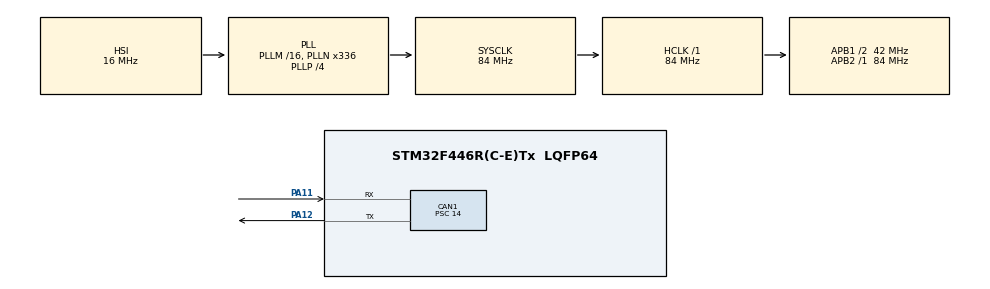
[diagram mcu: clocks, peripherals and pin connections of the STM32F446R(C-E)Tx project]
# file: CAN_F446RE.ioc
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CAN1.BS1=CAN_BS1_2TQ
CAN1.BS2=CAN_BS2_3TQ
CAN1.CalculateBaudRate=499999
CAN1.CalculateTimeBit=2000
CAN1.CalculateTimeQuantum=333.33333333333337
CAN1.Prescaler=14
CAN1.SJW=CAN_SJW_2TQ
Mcu.Family=STM32F4
Mcu.Name=STM32F446R(C-E)Tx
Mcu.Package=LQFP64
NVIC.PriorityGroup=NVIC_PRIORITYGROUP_0
PA11.GPIO_PuPd=GPIO_PULLUP
PA11.Mode=CAN_Activate
PA11.Signal=CAN1_RX
PA12.Mode=CAN_Activate
PA12.Signal=CAN1_TX
ProjectManager.HeapSize=0x200
ProjectManager.StackSize=0x400
ProjectManager.TargetToolchain=STM32CubeIDE
RCC.48MHZClocksFreq_Value=84000000
RCC.AHBFreq_Value=84000000
RCC.APB1CLKDivider=RCC_HCLK_DIV2
RCC.APB1Freq_Value=42000000
RCC.APB1TimFreq_Value=84000000
RCC.APB2Freq_Value=84000000
RCC.APB2TimFreq_Value=84000000
RCC.CortexFreq_Value=84000000
RCC.FLatency-AdvancedSettings=FLASH_LATENCY_2
RCC.HCLKFreq_Value=84000000
RCC.HSE_VALUE=8000000
RCC.HSI_VALUE=16000000
RCC.PLLN=336
RCC.PLLP=RCC_PLLP_DIV4
RCC.SYSCLKFreq_VALUE=84000000
RCC.SYSCLKSource=RCC_SYSCLKSOURCE_PLLCLK
RCC.USBFreq_Value=168000000
RCC.VCOOutputFreq_Value=336000000
board=NUCLEO-F446RE

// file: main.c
/* USER CODE BEGIN Header */
/**
  ******************************************************************************
  * @file           : main.c
  * @brief          : Main program body
  * Author	    : Le Viet Duc
  ******************************************************************************
  * @attention
  *
  * Copyright (c) 2024 STMicroelectronics.
  * All rights reserved.
  *
  * This software is licensed under terms that can be found in the LICENSE file
  * in the root directory of this software component.
  * If no LICENSE file comes with this software, it is provided AS-IS.
  *
  ******************************************************************************
  */
/* USER CODE END Header */
#include "main.h"

CAN_HandleTypeDef hcan1;

void SystemClock_Config(void);
static void MX_GPIO_Init(void);
static void MX_CAN1_Init(void);
void Transmit(void);

/* USER CODE BEGIN 0 */

CAN_TxHeaderTypeDef   TxHeader;
CAN_RxHeaderTypeDef   RxHeader;

uint8_t               TxData[8];
uint8_t               RxData[8];

uint32_t              TxMailbox;

/* USER CODE END 0 */

int main(void)
{

  /* MCU Configuration--------------------------------------------------------*/

  /* Reset of all peripherals, Initializes the Flash interface and the Systick. */
  HAL_Init();

  /* Configure the system clock */
  SystemClock_Config();

  /* Initialize all configured peripherals */
  MX_GPIO_Init();
  MX_CAN1_Init();
  /* USER CODE BEGIN 2 */

  HAL_CAN_Start(&hcan1);

  // Activate the notification
  HAL_CAN_ActivateNotification(&hcan1, CAN_IT_RX_FIFO0_MSG_PENDING);

  /* USER CODE END 2 */

  /* Infinite loop */
  while (1)
  {

    /* USER CODE BEGIN 3 */
	  Transmit();

	  HAL_CAN_GetRxMessage(&hcan1, CAN_RX_FIFO0, &RxHeader, RxData);

  }
  /* USER CODE END 3 */
}

void SystemClock_Config(void)
{
  RCC_OscInitTypeDef RCC_OscInitStruct = {0};
  RCC_ClkInitTypeDef RCC_ClkInitStruct = {0};

  /** Configure the main internal regulator output voltage
  */
  __HAL_RCC_PWR_CLK_ENABLE();
  __HAL_PWR_VOLTAGESCALING_CONFIG(PWR_REGULATOR_VOLTAGE_SCALE3);

  /** Initializes the RCC Oscillators according to the specified parameters
  * in the RCC_OscInitTypeDef structure.
  */
  RCC_OscInitStruct.OscillatorType = RCC_OSCILLATORTYPE_HSI;
  RCC_OscInitStruct.HSIState = RCC_HSI_ON;
  RCC_OscInitStruct.HSICalibrationValue = RCC_HSICALIBRATION_DEFAULT;
  RCC_OscInitStruct.PLL.PLLState = RCC_PLL_ON;
  RCC_OscInitStruct.PLL.PLLSource = RCC_PLLSOURCE_HSI;
  RCC_OscInitStruct.PLL.PLLM = 16;
  RCC_OscInitStruct.PLL.PLLN = 336;
  RCC_OscInitStruct.PLL.PLLP = RCC_PLLP_DIV4;
  RCC_OscInitStruct.PLL.PLLQ = 2;
  RCC_OscInitStruct.PLL.PLLR = 2;
  if (HAL_RCC_OscConfig(&RCC_OscInitStruct) != HAL_OK)
  {
    Error_Handler();
  }

  /** Initializes the CPU, AHB and APB buses clocks
  */
  RCC_ClkInitStruct.ClockType = RCC_CLOCKTYPE_HCLK|RCC_CLOCKTYPE_SYSCLK
                              |RCC_CLOCKTYPE_PCLK1|RCC_CLOCKTYPE_PCLK2;
  RCC_ClkInitStruct.SYSCLKSource = RCC_SYSCLKSOURCE_PLLCLK;
  RCC_ClkInitStruct.AHBCLKDivider = RCC_SYSCLK_DIV1;
  RCC_ClkInitStruct.APB1CLKDivider = RCC_HCLK_DIV2;
  RCC_ClkInitStruct.APB2CLKDivider = RCC_HCLK_DIV1;

  if (HAL_RCC_ClockConfig(&RCC_ClkInitStruct, FLASH_LATENCY_2) != HAL_OK)
  {
    Error_Handler();
  }
}

static void MX_CAN1_Init(void)
{

  hcan1.Instance = CAN1;
  hcan1.Init.Prescaler = 14;
  hcan1.Init.Mode = CAN_MODE_NORMAL;
  hcan1.Init.SyncJumpWidth = CAN_SJW_2TQ;
  hcan1.Init.TimeSeg1 = CAN_BS1_2TQ;
  hcan1.Init.TimeSeg2 = CAN_BS2_3TQ;
  hcan1.Init.TimeTriggeredMode = DISABLE;
  hcan1.Init.AutoBusOff = DISABLE;
  hcan1.Init.AutoWakeUp = DISABLE;
  hcan1.Init.AutoRetransmission = DISABLE;
  hcan1.Init.ReceiveFifoLocked = DISABLE;
  hcan1.Init.TransmitFifoPriority = DISABLE;
  if (HAL_CAN_Init(&hcan1) != HAL_OK)
  {
    Error_Handler();
  }
  /* USER CODE BEGIN CAN1_Init 2 */

  CAN_FilterTypeDef canfilterconfig;

  canfilterconfig.FilterActivation = CAN_FILTER_ENABLE;
  canfilterconfig.FilterBank = 18;  // which filter bank to use from the assigned ones
  canfilterconfig.FilterFIFOAssignment = CAN_FILTER_FIFO0;
  canfilterconfig.FilterIdHigh = 0x0000;
  canfilterconfig.FilterIdLow = 0x0000;
  canfilterconfig.FilterMaskIdHigh = 0x0000;
  canfilterconfig.FilterMaskIdLow = 0x0000;
  canfilterconfig.FilterMode = CAN_FILTERMODE_IDMASK;
  canfilterconfig.FilterScale = CAN_FILTERSCALE_32BIT;
  canfilterconfig.SlaveStartFilterBank = 20;  // how many filters to assign to the CAN1 (master can)

  HAL_CAN_ConfigFilter(&hcan1, &canfilterconfig);

  /* USER CODE END CAN1_Init 2 */

}

static void MX_GPIO_Init(void)
{

  /* GPIO Ports Clock Enable */
  __HAL_RCC_GPIOA_CLK_ENABLE();

}

void Error_Handler(void)
{
  __disable_irq();
  while (1)
  {
  }
}

void Transmit(void)
{
	  TxHeader.DLC = 8;  // data length
	  TxHeader.IDE = CAN_ID_STD;
	  TxHeader.RTR = CAN_RTR_DATA;
	  TxHeader.StdId = 0x446;  // ID

	  TxData[0] = 0x01;
	  TxData[1] = 0x02;
	  TxData[2] = 0x03;
	  TxData[3] = 0x04;
	  TxData[4] = 0x05;
	  TxData[5] = 0x06;
	  TxData[6] = 0x07;
	  TxData[7] = 0x08;

	  HAL_CAN_AddTxMessage(&hcan1, &TxHeader, TxData, &TxMailbox);
}
